# gcr_me17 register map
Registers are access not given, no defined reset value unless marked. A register's access mark holds for its fields unless they carry their own. Offsets are from the block's base; lines under a group give offsets from that group; [hi:lo] are bit positions; {n}, {i} and the like mark numbered series; 'fields as' and 'values as' point back to an identical list; <NAME> marks a mode.

## Memory map
0x40000000 GCR size 0x400 — Global Control Registers.

## GCR — Global Control Registers.
Base 0x40000000
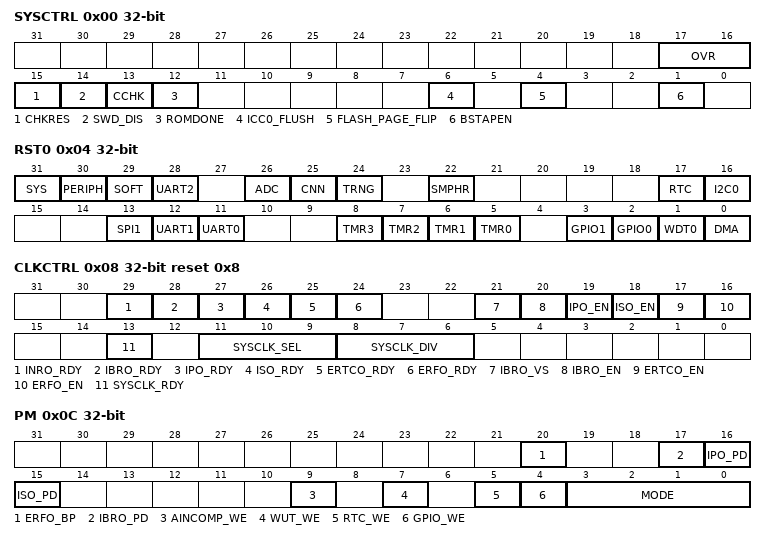
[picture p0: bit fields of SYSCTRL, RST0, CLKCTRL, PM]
0x00 SYSCTRL — System Control.
  [17:16] OVR — Operating Voltage Range.
  [15] CHKRES — ROM Checksum Result. This bit is only valid when CHKRD=1.
    0=pass (ROM Checksum Correct.); 1=fail (ROM Checksum Fail.)
  [14] SWD_DIS — Serial Wire Debug Disable. This bit is used to disable the serial wire debug interface This bit is only writeable if (FMV lock word is not programmed) or if (ICE lock word is not programmed and the ROM_DONE bit is not set).
  [13] CCHK — Compute ROM Checksum. This bit is self-cleared when calculation is completed. Once set, software clearing this bit is ignored and the bit will remain set until the operation is completed.
    0=complete (No operation/complete.); 1=Start operation
  [12] ROMDONE — ROM_DONE status. Used to disable SWD interface during system initialization procedure
  [6] ICC0_FLUSH — Code Cache Flush. This bit is used to flush the code caches and the instruction buffer of the Cortex-M4.
    0=Normal Code Cache Operation; 1=flush (Code Caches and CPU instruction buffer are flushed)
  [4] FLASH_PAGE_FLIP — Flips the Flash bottom and top halves. (Depending on the total flash size, each half is either 256K or 512K). Initiating a flash page flip will cause a flush of both the data buffer on the DCODE bus and the internal instruction buffer.
    0=normal (Physical layout matches logical layout.); 1=swapped (Bottom half mapped to logical top half and vice versa.)
  [1] BSTAPEN — Boundary Scan TAP enable. When enabled, the JTAG port is conneted to the Boundary Scan TAP instead of the ARM ICE.
0x04 RST0 — Reset.
  [all] fields
    0=reset_done (Reset complete.); 1=busy (Starts Reset or indicates reset in progress.)
  [31] SYS — System Reset. Setting this bit to 1 resets the CPU core and all peripherals, including the watchdog timer.
  [30] PERIPH — Peripheral Reset. Setting this bit to 1 resets all peripherals. The CPU core, the watchdog timer, and all GPIO pins are unaffected by this reset.
  [29] SOFT — Soft Reset. Setting this bit to 1 resets everything except the CPU and the watchdog timer.
  [28] UART2 — UART2 Reset. Setting this bit to 1 resets all UART 2 blocks.
  [26] ADC — ADC Reset.
  [25] CNN — CNN Reset.
  [24] TRNG — TRNG Reset. This reset is only available during the manufacture testing phase.
  [22] SMPHR — Semaphore Reset.
  [17] RTC — Real Time Clock Reset.
  [16] I2C0 — I2C 0 Reset.
  [13] SPI1 — SPI 1 Reset. Setting this bit to 1 resets all SPI 1 blocks.
  [12] UART1 — UART 1 Reset. Setting this bit to 1 resets all UART 1 blocks.
  [11] UART0 — UART 0 Reset. Setting this bit to 1 resets all UART 0 blocks.
  [n+5] TMR{n} (n=0..3) — Timer {n} Reset. Setting this bit to 1 resets Timer {n} blocks.
  [3] GPIO1 — GPIO1 Reset. Setting this bit to 1 resets GPIO1 pins to their default states.
  [2] GPIO0 — GPIO0 Reset. Setting this bit to 1 resets GPIO0 pins to their default states.
  [1] WDT0 — Watchdog Timer 0 Reset.
  [0] DMA — DMA Reset.
0x08 CLKCTRL reset 0x8 — Clock Control.
  [29] INRO_RDY ro — 8 kHz Low Frequency Reference Clock Ready.
    0=not (Is not Ready.); 1=ready (Is Ready.)
  [28] IBRO_RDY ro — 7.3725 MHz HIRC Ready.
    0=not (Is not Ready.); 1=ready (Is Ready.)
  [27] IPO_RDY ro — 100 MHz HIRC Ready.
    0=not (Is not Ready.); 1=ready (Is Ready.)
  [26] ISO_RDY ro — 60 MHz HIRC Ready.
    0=not (Is not Ready.); 1=ready (Is Ready.)
  [25] ERTCO_RDY ro — 32 kHz Crystal Oscillator Ready
    0=not (Is not Ready.); 1=ready (Is Ready.)
  [24] ERFO_RDY ro — 32MHz Crystal Oscillator Ready
    0=not (Is not Ready.); 1=ready (Is Ready.)
  [21] IBRO_VS — 7.3725 MHz High Frequency Internal Reference Clock Voltage Select. This register bit is used to select the power supply to the IBRO.
    0=VCore Supply; 1=1V (Dedicated 1V regulated supply.)
  [20] IBRO_EN — 7.3725 MHz High Frequency Internal Reference Clock Enable.
    0=dis (Is Disabled.); 1=en (Is Enabled.)
  [19] IPO_EN — 100 MHz High Frequency Internal Reference Clock Enable.
    0=dis (Is Disabled.); 1=en (Is Enabled.)
  [18] ISO_EN — 60 MHz High Frequency Internal Reference Clock Enable.
    0=dis (Is Disabled.); 1=en (Is Enabled.)
  [17] ERTCO_EN — 32 kHz Crystal Oscillator Enable.
    0=dis (Is Disabled.); 1=en (Is Enabled.)
  [16] ERFO_EN — 32MHz Crystal Oscillator Enable.
    0=dis (Is Disabled.); 1=en (Is Enabled.)
  [13] SYSCLK_RDY ro — Clock Ready. This read only bit reflects whether the currently selected system clock source is running.
    0=busy (Switchover to the new clock source (as selected by CLKSEL) has not yet occurred.); 1=ready (System clock running from CLKSEL clock source.)
  [11:9] SYSCLK_SEL — Clock Source Select. This 3 bit field selects the source for the system clock.
    0=ISO (The internal 60 MHz oscillator is used for the system clock.); 2=ERFO (32MHz Crystal is used for the system clock.); 3=INRO (8 kHz LIRC is used for the system clock.); 4=IPO (The internal 96 MHz oscillator is used for the system clock.); 5=IBRO (The internal 7.3725 MHz oscillator is used for the system clock.); 6=ERTCO (32 kHz is used for the system clock.); 7=EXTCLK (External clock on GPIO0.30.)
  [8:6] SYSCLK_DIV — Prescaler Select. This 3 bit field sets the system operating frequency by controlling the prescaler that divides the output of the PLL0.
    0=div1 (Divide by 1.); 1=div2 (Divide by 2.); 2=div4 (Divide by 4.); 3=div8 (Divide by 8.); 4=div16 (Divide by 16.); 5=div32 (Divide by 32.); 6=div64 (Divide by 64.); 7=div128 (Divide by 128.)
0x0C PM — Power Management.
  [20] ERFO_BP — 32MHz Oscillator Bypass
  [17] IBRO_PD — 7.3725 MHz power down. This bit selects 7.3725 MHz clock power state in DEEPSLEEP mode.
    0=active (Mode is Active.); 1=deepsleep (Powered down in DEEPSLEEP.)
  [16] IPO_PD — 100 MHz power down. This bit selects 100 MHz clock power state in DEEPSLEEP mode.
    values as IBRO_PD
  [15] ISO_PD — 60 MHz power down. This bit selects the 60 MHz clock power state in DEEPSLEEP mode.
    values as IBRO_PD
  [9] AINCOMP_WE — AIN COMP Wake Up Enable. This bit enables AIN COMP as wakeup source.
    0=dis (Wake Up Disable.); 1=en (Wake Up Enable.)
  [7] WUT_WE — WUT Wake Up Enable. This bit enables the Wake-Up Timer as wakeup source.
    0=dis (Wake Up Disable.); 1=en (Wake Up Enable.)
  [5] RTC_WE — RTC Alarm Wake Up Enable. This bit enables RTC alarm as wakeup source. If enabled, the desired RTC alarm must be configured via the RTC control registers.
    0=dis (Wake Up Disable.); 1=en (Wake Up Enable.)
  [4] GPIO_WE — GPIO Wake Up Enable. This bit enables all GPIO pins as potential wakeup sources. Any GPIO configured for wakeup is capable of causing an exit from IDLE or STANDBY modes when this bit is set.
    0=dis (Wake Up Disable.); 1=en (Wake Up Enable.)
  [3:0] MODE — Operating Mode. This two bit field selects the current operating mode for the device. Note that code execution only occurs during ACTIVE mode.
    0=Active Mode; 1=sleep (Cortex-M4 Active, RISC-V Sleep Mode.); 2=Standby Mode; 4=Backup Mode; 8=lpm (LPM or CM4 Deep Sleep Mode.); 9=upm; 10=Power Down Mode
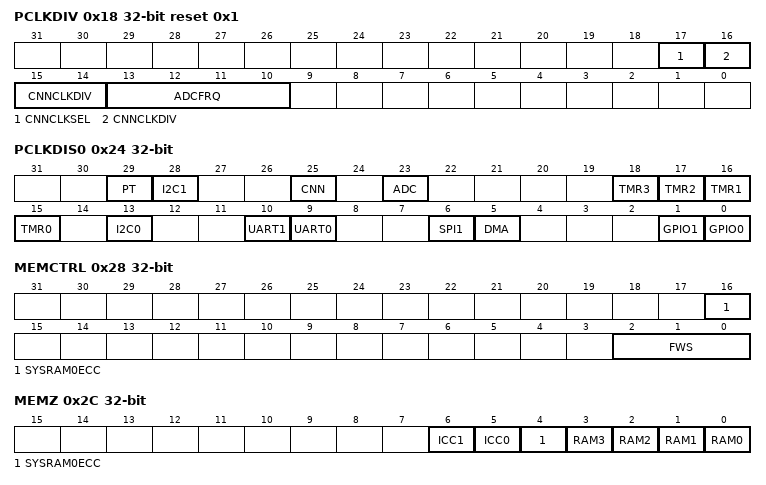
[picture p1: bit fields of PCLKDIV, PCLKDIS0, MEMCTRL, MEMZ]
0x18 PCLKDIV reset 0x1 — Peripheral Clock Divider.
  [17] CNNCLKSEL — CNN Clock Select.
    0=system; 1=IBRO60
  [16:14] CNNCLKDIV — CNN Clock Divider.
    0=div2; 1=div4; 2=div8; 3=div16; 4=div1
  [13:10] ADCFRQ — ADC clock Frequency. These bits define the ADC clock frequency. fADC = fPCLK / (ADCFRQ)
0x24 PCLKDIS0 — Peripheral Clock Disable.
  [all] fields
    0=en (enable it.); 1=dis (disable it.)
  [29] PT — Pluse Train Clock Disable.
  [28] I2C1 — I2C 1 Clock Disable.
  [25] CNN — CNN Clock Disable.
  [23] ADC — ADC Clock Disable.
  [n+15] TMR{n} (n=0..3) — Timer {n} Clock Disable.
  [13] I2C0 — I2C 0 Clock Disable.
  [10] UART1 — UART 1 Clock Disable.
  [9] UART0 — UART 0 Clock Disable.
  [6] SPI1 — SPI 1 Clock Disable.
  [5] DMA — DMA Clock Disable.
  [1] GPIO1 — GPIO1 Clock Disable.
  [0] GPIO0 — GPIO0 Clock Disable.
0x28 MEMCTRL — Memory Clock Control Register.
  [16] SYSRAM0ECC — SYSRAM0 ECC Select.
  [2:0] FWS — Flash Wait State. These bits define the number of wait-state cycles per Flash data read access. Minimum wait state is 2.
0x2C MEMZ — Memory Zeroize Control.
  [all] fields
    0=nop (No operation/complete.); 1=Start operation
  [6] ICC1 — Instruction Cachei 1 Zeroization.
  [5] ICC0 — Instruction Cachei 0 Zeroization.
  [4] SYSRAM0ECC — System RAM 0 ECC Zeroization.
  [n] RAM{n} (n=0..3) — System RAM Block {n} Zeroization.
0x40 SYSST — System Status Register.
  [0] ICELOCK — ARM ICE Lock Status.
    0=unlocked (ICE is unlocked.); 1=locked (ICE is locked.)
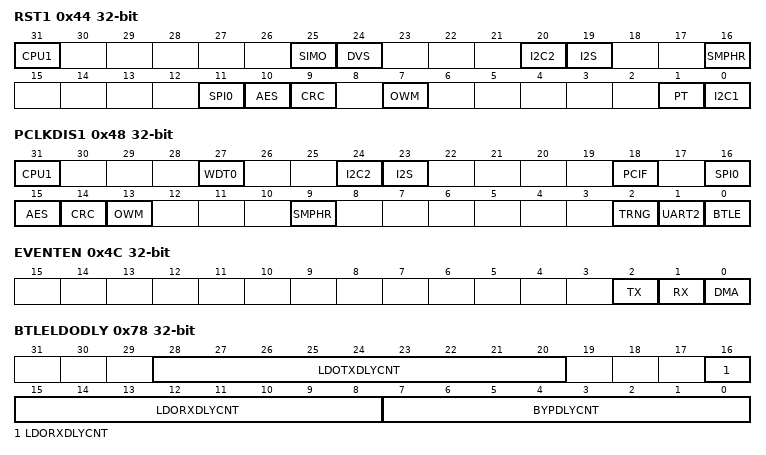
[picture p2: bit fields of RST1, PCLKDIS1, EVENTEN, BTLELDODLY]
0x44 RST1 — Reset 1.
  [all] fields
    on read: 0=reset_done (Reset complete.); 1=busy (Starts reset or indicates reset in progress.)
  [31] CPU1 — CPU1 Reset.
  [25] SIMO — SIMO Reset.
  [24] DVS — DVS Reset.
  [20] I2C2 — I2C2 Reset.
  [19] I2S — I2S Reset.
  [16] SMPHR — SMPHR Reset.
  [11] SPI0 — SPI 0 Reset.
  [10] AES — AES Reset.
  [9] CRC — CRC Reset.
  [7] OWM — OWM Reset.
  [1] PT — PT Reset.
  [0] I2C1 — I2C1 Reset.
0x48 PCLKDIS1 — Peripheral Clock Disable.
  [31] CPU1 — CPU1 Clock Disable.
    0=en (Enable.); 1=dis (Disable.)
  [27] WDT0 — Watch Dog Timer 0 Clock Disable.
    0=en (Enable.); 1=dis (Disable.)
  [24] I2C2 — I2C2 Clock Disable.
    0=en (Enable.); 1=dis (Disable.)
  [23] I2S — I2S Clock Disable.
    0=en (Enable.); 1=dis (Disable.)
  [18] PCIF — Parallel Camera Interface Clock Disable.
    0=en (Enable.); 1=dis (Disable.)
  [16] SPI0 — SPI 0 Clock Disable.
    0=en (Enable.); 1=dis (Disable.)
  [15] AES — AES Clock Disable.
    0=en (Enable.); 1=dis (Disable.)
  [14] CRC — CRC Clock Disable.
    0=en (Enable.); 1=dis (Disable.)
  [13] OWM — One-Wire Clock Disable.
    0=en (Enable.); 1=dis (Disable.)
  [9] SMPHR — SMPHR Clock Disable.
    0=en (Enable.); 1=dis (Disable.)
  [2] TRNG — TRNG Clock Disable.
    0=en (Enable.); 1=dis (Disable.)
  [1] UART2 — UART2 Clock Disable.
    0=en (Enable.); 1=dis (Disable.)
  [0] BTLE — Bluetooth Clock Disable.
0x4C EVENTEN — Event Enable Register.
  [2] TX — Enable TXEV pin event. When this bit is set, TXEV event from the CPU is output to GPIO1.9.
  [1] RX — Enable RXEV pin event. When this bit is set, a logic high of GPIO1.8 will cause an RXEV event to wake the CPU from WFE sleep mode.
  [0] DMA — Enable DMA event. When this bit is set, a DMA event will cause an RXEV event to wake the CPU from WFE sleep mode.
0x50 REVISION ro
  [15:0] REVISION — Manufacturer Chip Revision.
0x54 SYSIE — System Status Interrupt Enable Register.
  [0] ICEUNLOCK — ARM ICE Unlock Interrupt Enable.
    0=dis (disabled.); 1=en (enabled.)
0x64 ECCERR — ECC Error Register
  [0] RAM — ECC System RAM0 Error Flag. Write 1 to clear.
0x68 ECCCED — ECC Not Double Error Detect Register
  [0] RAM — ECC System RAM0 Error Flag. Write 1 to clear.
0x6C ECCIE — ECC IRQ Enable Register
  [0] RAM — ECC System RAM0 Error Interrup Enable
0x70 ECCADDR — ECC Error Address Register
  [31:0] ECCERRAD — ECC Error Address.
0x74 BTLELDOCTRL — BTLE LDO Control Register
  [15] LDOTXBYPENENDLY — LDOTX Bypass Enable Delay.
  [14] LDORXBYPENENDLY — LDORX Bypass Enable Delay.
  [13] LDORXENDLY — LDORX Enable Delay.
  [12] LDOTXENDLY — LDOTX Enable Delay.
  [11] LDOTXDISCH — LDOTX Discharge.
  [10] LDOTXBYP — LDOTX Bypass Enable.
  [9] LDORXDISCH — LDORX Discharge.
  [8] LDORXBYP — LDORX Bypass Enable.
  [7] LDORXVSEL1 — LDORX Voltage Setting.
  [7:6] LDORXVSEL — LDORX Voltage Setting.
    0=0_7 (0.7V); 1=0.85V; 2=0_9 (0.9V); 3=1.1V
  [6] LDORXVSEL0 — LDORX Voltage Setting.
  [5] LDORXPULLD — LDOrX Pull Down.
  [4] LDORXEN — LDORX Enable.
  [3] LDOTXVSEL1 — LDOTX Voltage Setting.
  [3:2] LDOTXVSEL — LDOTX Voltage Setting.
    0=0_7 (0.7V); 1=0.85V; 2=0_9 (0.9V); 3=1.1V
  [2] LDOTXVSEL0 — LDOTX Voltage Setting.
  [1] LDOTXPULLD — LDOTX Pull Down.
  [0] LDOTXEN — LDOTX Enable.
0x78 BTLELDODLY — BTLE LDO Delay Register
  [28:20] LDOTXDLYCNT — LDOTX Delay Count.
  [16:8] LDORXDLYCNT — LDORX Delay Count.
  [7:0] BYPDLYCNT — Bypass Delay Count.
0x80 GPR — General Purpose Register.
